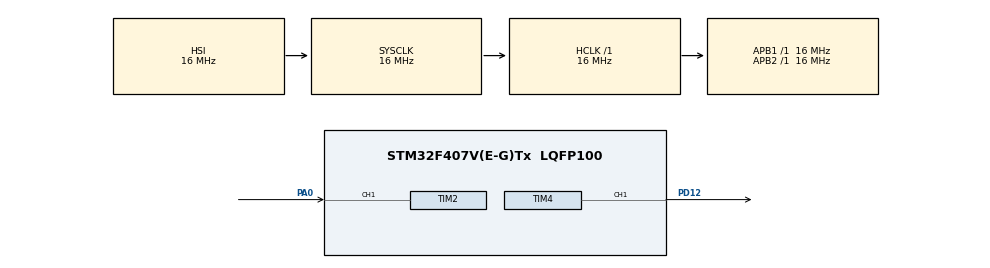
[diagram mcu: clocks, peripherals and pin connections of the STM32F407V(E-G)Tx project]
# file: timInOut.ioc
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Mcu.Family=STM32F4
Mcu.Name=STM32F407V(E-G)Tx
Mcu.Package=LQFP100
NVIC.PriorityGroup=NVIC_PRIORITYGROUP_4
PA0-WKUP.Signal=S_TIM2_CH1_ETR
PA13.Mode=Serial_Wire
PA13.Signal=SYS_JTMS-SWDIO
PA14.Mode=Serial_Wire
PA14.Signal=SYS_JTCK-SWCLK
PD12.Signal=S_TIM4_CH1
PH0-OSC_IN.Mode=HSE-External-Oscillator
PH0-OSC_IN.Signal=RCC_OSC_IN
PH1-OSC_OUT.Mode=HSE-External-Oscillator
PH1-OSC_OUT.Signal=RCC_OSC_OUT
ProjectManager.HeapSize=0x200
ProjectManager.StackSize=0x400
ProjectManager.TargetToolchain=STM32CubeIDE
RCC.AHBFreq_Value=16000000
RCC.APB1Freq_Value=16000000
RCC.APB2Freq_Value=16000000
RCC.CortexFreq_Value=16000000
RCC.HSE_VALUE=25000000
RCC.HSI_VALUE=16000000
RCC.LSE_VALUE=32768
RCC.SYSCLKFreq_VALUE=16000000
RCC.VCOOutputFreq_Value=192000000
SH.S_TIM2_CH1_ETR.0=TIM2_CH1,Input_Capture1_from_TI1
SH.S_TIM4_CH1.0=TIM4_CH1,Output Compare1 CH1
TIM2.Channel-Input_Capture1_from_TI1=TIM_CHANNEL_1
TIM2.Period=100000
TIM2.Prescaler=15999
TIM4.Channel-Output\ Compare1\ CH1=TIM_CHANNEL_1
TIM4.Period=1000
TIM4.Prescaler=15999
board=custom

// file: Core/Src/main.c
/* USER CODE BEGIN Header */
/**
  ******************************************************************************
  * @file           : main.c
  * @brief          : Main program body
  ******************************************************************************
  * @attention
  *
  * <h2><center>&copy; Copyright (c) 2020 STMicroelectronics.
  * All rights reserved.</center></h2>
  *
  * This software component is licensed by ST under BSD 3-Clause license,
  * the "License"; You may not use this file except in compliance with the
  * License. You may obtain a copy of the License at:
  *                        opensource.org/licenses/BSD-3-Clause
  *
  ******************************************************************************
  */
/* USER CODE END Header */
#include "main.h"

TIM_HandleTypeDef htim2;
TIM_HandleTypeDef htim4;

/* USER CODE BEGIN PV */
/* tanımlamalar */
uint32_t geciciGirisVerisi, girisSaklama;
/* USER CODE END PV */

void SystemClock_Config(void);
static void MX_GPIO_Init(void);
static void MX_TIM4_Init(void);
static void MX_TIM2_Init(void);

int main(void)
{

  /* MCU Configuration--------------------------------------------------------*/

  /* Reset of all peripherals, Initializes the Flash interface and the Systick. */
  HAL_Init();

  /* Configure the system clock */
  SystemClock_Config();

  /* Initialize all configured peripherals */
  MX_GPIO_Init();
  MX_TIM4_Init();
  MX_TIM2_Init();
  /* USER CODE BEGIN 2 */
  /* timer output compare başlatma */
  HAL_TIM_OC_Start(&htim4, TIM_CHANNEL_1);
  /* timer input capture interrupt başlatma */
  HAL_TIM_IC_Start_IT(&htim2, TIM_CHANNEL_1);
  /* USER CODE END 2 */

  /* Infinite loop */
  /* USER CODE BEGIN WHILE */
  while (1)
  {
	  /* veri saklama */
	  girisSaklama=__HAL_TIM_GetCounter(&htim2);
    /* USER CODE END WHILE */

  }
}

void SystemClock_Config(void)
{
  RCC_OscInitTypeDef RCC_OscInitStruct = {0};
  RCC_ClkInitTypeDef RCC_ClkInitStruct = {0};

  /** Configure the main internal regulator output voltage
  */
  __HAL_RCC_PWR_CLK_ENABLE();
  __HAL_PWR_VOLTAGESCALING_CONFIG(PWR_REGULATOR_VOLTAGE_SCALE1);
  /** Initializes the RCC Oscillators according to the specified parameters
  * in the RCC_OscInitTypeDef structure.
  */
  RCC_OscInitStruct.OscillatorType = RCC_OSCILLATORTYPE_HSI;
  RCC_OscInitStruct.HSIState = RCC_HSI_ON;
  RCC_OscInitStruct.HSICalibrationValue = RCC_HSICALIBRATION_DEFAULT;
  RCC_OscInitStruct.PLL.PLLState = RCC_PLL_NONE;
  if (HAL_RCC_OscConfig(&RCC_OscInitStruct) != HAL_OK)
  {
    Error_Handler();
  }
  /** Initializes the CPU, AHB and APB buses clocks
  */
  RCC_ClkInitStruct.ClockType = RCC_CLOCKTYPE_HCLK|RCC_CLOCKTYPE_SYSCLK
                              |RCC_CLOCKTYPE_PCLK1|RCC_CLOCKTYPE_PCLK2;
  RCC_ClkInitStruct.SYSCLKSource = RCC_SYSCLKSOURCE_HSI;
  RCC_ClkInitStruct.AHBCLKDivider = RCC_SYSCLK_DIV1;
  RCC_ClkInitStruct.APB1CLKDivider = RCC_HCLK_DIV1;
  RCC_ClkInitStruct.APB2CLKDivider = RCC_HCLK_DIV1;

  if (HAL_RCC_ClockConfig(&RCC_ClkInitStruct, FLASH_LATENCY_0) != HAL_OK)
  {
    Error_Handler();
  }
}

static void MX_TIM2_Init(void)
{

  TIM_MasterConfigTypeDef sMasterConfig = {0};
  TIM_IC_InitTypeDef sConfigIC = {0};

  htim2.Instance = TIM2;
  htim2.Init.Prescaler = 15999;
  htim2.Init.CounterMode = TIM_COUNTERMODE_UP;
  htim2.Init.Period = 100000;
  htim2.Init.ClockDivision = TIM_CLOCKDIVISION_DIV1;
  htim2.Init.AutoReloadPreload = TIM_AUTORELOAD_PRELOAD_DISABLE;
  if (HAL_TIM_IC_Init(&htim2) != HAL_OK)
  {
    Error_Handler();
  }
  sMasterConfig.MasterOutputTrigger = TIM_TRGO_RESET;
  sMasterConfig.MasterSlaveMode = TIM_MASTERSLAVEMODE_DISABLE;
  if (HAL_TIMEx_MasterConfigSynchronization(&htim2, &sMasterConfig) != HAL_OK)
  {
    Error_Handler();
  }
  sConfigIC.ICPolarity = TIM_INPUTCHANNELPOLARITY_RISING;
  sConfigIC.ICSelection = TIM_ICSELECTION_DIRECTTI;
  sConfigIC.ICPrescaler = TIM_ICPSC_DIV1;
  sConfigIC.ICFilter = 0;
  if (HAL_TIM_IC_ConfigChannel(&htim2, &sConfigIC, TIM_CHANNEL_1) != HAL_OK)
  {
    Error_Handler();
  }

}

static void MX_TIM4_Init(void)
{

  TIM_MasterConfigTypeDef sMasterConfig = {0};
  TIM_OC_InitTypeDef sConfigOC = {0};

  htim4.Instance = TIM4;
  htim4.Init.Prescaler = 15999;
  htim4.Init.CounterMode = TIM_COUNTERMODE_UP;
  htim4.Init.Period = 1000;
  htim4.Init.ClockDivision = TIM_CLOCKDIVISION_DIV1;
  htim4.Init.AutoReloadPreload = TIM_AUTORELOAD_PRELOAD_DISABLE;
  if (HAL_TIM_OC_Init(&htim4) != HAL_OK)
  {
    Error_Handler();
  }
  sMasterConfig.MasterOutputTrigger = TIM_TRGO_RESET;
  sMasterConfig.MasterSlaveMode = TIM_MASTERSLAVEMODE_DISABLE;
  if (HAL_TIMEx_MasterConfigSynchronization(&htim4, &sMasterConfig) != HAL_OK)
  {
    Error_Handler();
  }
  sConfigOC.OCMode = TIM_OCMODE_TIMING;
  sConfigOC.Pulse = 0;
  sConfigOC.OCPolarity = TIM_OCPOLARITY_HIGH;
  sConfigOC.OCFastMode = TIM_OCFAST_DISABLE;
  if (HAL_TIM_OC_ConfigChannel(&htim4, &sConfigOC, TIM_CHANNEL_1) != HAL_OK)
  {
    Error_Handler();
  }
  HAL_TIM_MspPostInit(&htim4);

}

static void MX_GPIO_Init(void)
{

  /* GPIO Ports Clock Enable */
  __HAL_RCC_GPIOH_CLK_ENABLE();
  __HAL_RCC_GPIOA_CLK_ENABLE();
  __HAL_RCC_GPIOD_CLK_ENABLE();

}

/* USER CODE BEGIN 4 */
/* input capture fonksiyonu için callback fonksiyonu */
void HAL_TIM_IC_CaptureCallback(TIM_HandleTypeDef *htim)
{
	if(htim->Instance == TIM2)
	{
		geciciGirisVerisi = __HAL_TIM_GetCounter(htim);
		__HAL_TIM_SetCounter(htim, 0);
	}
}
/* USER CODE END 4 */

void Error_Handler(void)
{
  __disable_irq();
  while (1)
  {
  }
}

/************************ (C) COPYRIGHT STMicroelectronics *****END OF FILE****/
